# MCU_NAVSS0_RINGACC0_UDMASS_RINGACC0_ISC register map
Vendor: Texas Instruments
Peripheral module from a debugger description file (folder J721S2).
Registers are 32-bit, access not given, reset 0x0 unless marked. A register's access mark holds for its fields unless they carry their own. Offsets are as the file gives them; lines under a group give offsets from that group; [hi:lo] are bit positions; {n}, {i} and the like mark numbered series; 'fields as' and 'values as' point back to an identical list; <NAME> marks a mode.

## MCU_NAVSS0_RINGACC0_UDMASS_RINGACC0_ISC
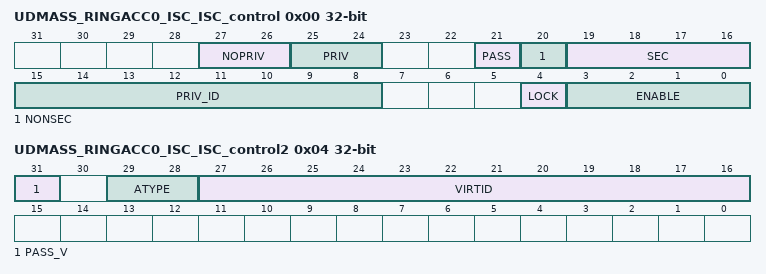
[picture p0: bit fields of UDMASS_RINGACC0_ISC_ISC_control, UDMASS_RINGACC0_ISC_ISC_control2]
0x00 UDMASS_RINGACC0_ISC_ISC_control — The ISC a Region b Control Register defines the control fields for the ISC.
  [27:26] NOPRIV rw — Clear output priv attribute. If each bit is set then the outgoing priv bit is cleared. Has precedence over priv set bits.
  [25:24] PRIV rw — Set outgoing priv attribute. If each bit is set then the outgoing priv bit is set.
  [21] PASS rw — No privID replacement, pass through value.
  [20] NONSEC rw — Make outgoing non-secure. Has precedence over secure enable bits.
  [19:16] SEC rw — Make outgoing secure. A value of 0xA enables, others disable.
  [15:8] PRIV_ID rw
  [4] LOCK — Lock region. Once set the region values cannot be modified. (access R/W1TS)
  [3:0] ENABLE rw — Enable region. A value of 0xA enables, others disable.
0x04 UDMASS_RINGACC0_ISC_ISC_control2 rw — The ISC a Region b Control Register 2 defines the control fields for the ISC.
  [31] PASS_V — No virtID replacement, pass through value.
  [29:28] ATYPE — Defines the output address type. 0 = physical no memory attributes. 1 = intermediate. 2 = virtual. 3 = physical with memory attributes.
  [27:16] VIRTID
